VERSION ""

NS_ :

BS_:

BU_:

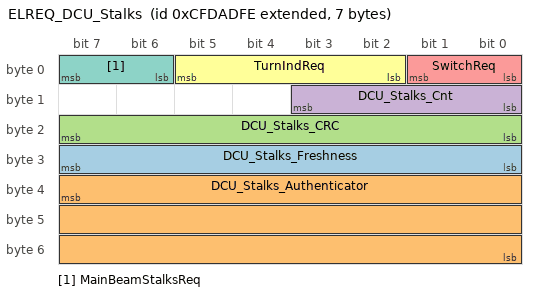
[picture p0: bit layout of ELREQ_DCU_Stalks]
BO_ 2365435390 ELREQ_DCU_Stalks: 7 Vector__XXX
 SG_ DCU_Stalks_Freshness : 31|8@0+ (1,0) [0|255] "" Vector__XXX
 SG_ DCU_Stalks_Authenticator : 39|24@0+ (1,0) [0|16777215] "" Vector__XXX
 SG_ DCU_Stalks_CRC : 16|8@1+ (1,0) [0|0] "" Vector__XXX
 SG_ DCU_Stalks_Cnt : 8|4@1+ (1,0) [0|0] "" Vector__XXX
 SG_ SwitchReq : 0|2@1+ (1,0) [0|3] "" Vector__XXX
 SG_ TurnIndReq : 2|4@1+ (1,0) [0|3] "" Vector__XXX
 SG_ MainBeamStalksReq : 6|2@1+ (1,0) [0|3] "" Vector__XXX

BO_ 2381722110 ELSTS: 1 Vector__XXX
 SG_ LampState : 0|3@1+ (1,0) [0|7] "" Vector__XXX
 SG_ ELSReadyToSleep : 3|2@1+ (1,0) [0|3] "" Vector__XXX

CM_ "$File: //depot/auto/dbc/Software_Modules/Exterior_Lights/ExtLightsSystem/0.3.4.0/ExtLightsSystem.dbc $
$Change: 215975 $
$DateTime: 2024/08/21 10:05:30 $
$Revision: #1 $";
CM_ BO_ 2365435390 "The message containing the request on external light sources from the operator's external light control switch(s).";
CM_ SG_ 2365435390 SwitchReq "A 2 bit parameter to indicate the selected position of operator's switch";
CM_ SG_ 2365435390 TurnIndReq "A 4 bit parameter to indicate the selected position of the operator's turn signal stalk";
CM_ SG_ 2365435390 MainBeamStalksReq "A 2 bit parameter to indicate the selected position of the operator's main light stalk";
CM_ BO_ 2381722110 "This lighting message is a response to the request for lighting data in the Exterior Lighting Command message.";
CM_ SG_ 2381722110 LampState "This parameter provides measured data from a center brake lamps

00 De activated
01 Activated
10 Fault Detected
11 Not Available";
BA_DEF_  "DBName" STRING ;
BA_DEF_ SG_  "SigType" ENUM  "Default","Range","RangeSigned","ASCII","Discrete","Control","ReferencePGN","DTC","StringDelimiter","StringLength","StringLengthControl","MessageCounter","MessageChecksum";
BA_DEF_ SG_  "GenSigSendType" ENUM  "Cyclic","OnWrite","OnWriteWithRepetition","OnChange","OnChangeWithRepetition","IfActive","IfActiveWithRepetition","NoSigSendType";
BA_DEF_ SG_  "GenSigILSupport" ENUM  "No","Yes";
BA_DEF_ SG_  "GenSigEVName" STRING ;
BA_DEF_ BO_  "GenMsgCycleTimeFast" INT 0 3600000;
BA_DEF_ BO_  "GenMsgILSupport" ENUM  "No","Yes";
BA_DEF_ BO_  "GenMsgDelayTime" INT 0 1000;
BA_DEF_ BO_  "GenMsgRequestable" INT 0 1;
BA_DEF_ BO_  "GenMsgSendType" ENUM  "cyclic","NotUsed","NotUsed","NotUsed","NotUsed","NotUsed","NotUsed","IfActive","noMsgSendType";
BA_DEF_ BO_  "VFrameFormat" ENUM  "StandardCAN","ExtendedCAN","reserved","J1939PG";
BA_DEF_ BO_  "GenMsgCycleTime" INT 0 3600000;
BA_DEF_ BO_  "SendOnChange" ENUM  "No","Yes";
BA_DEF_ BU_  "NmStationAddress" INT 0 255;
BA_DEF_  "SAE_J1939_DA_SpecVersion" STRING ;
BA_DEF_  "SAE_J1939_81_SpecVersion" STRING ;
BA_DEF_  "DatabaseVersion" STRING ;
BA_DEF_  "BusType" STRING ;
BA_DEF_  "ProtocolType" STRING ;
BA_DEF_  "SAE_J1939_75_SpecVersion" STRING ;
BA_DEF_  "SAE_J1939_21_SpecVersion" STRING ;
BA_DEF_  "SAE_J1939_73_SpecVersion" STRING ;
BA_DEF_  "SAE_J1939_71_SpecVersion" STRING ;
BA_DEF_ BO_  "Producer" STRING ;
BA_DEF_DEF_  "DBName" "";
BA_DEF_DEF_  "SigType" "Default";
BA_DEF_DEF_  "GenSigSendType" "NoSigSendType";
BA_DEF_DEF_  "GenSigILSupport" "Yes";
BA_DEF_DEF_  "GenSigEVName" "Env@Nodename_@Signame";
BA_DEF_DEF_  "GenMsgCycleTimeFast" 0;
BA_DEF_DEF_  "GenMsgILSupport" "Yes";
BA_DEF_DEF_  "GenMsgDelayTime" 0;
BA_DEF_DEF_  "GenMsgRequestable" 1;
BA_DEF_DEF_  "GenMsgSendType" "noMsgSendType";
BA_DEF_DEF_  "VFrameFormat" "J1939PG";
BA_DEF_DEF_  "GenMsgCycleTime" 0;
BA_DEF_DEF_  "SendOnChange" "No";
BA_DEF_DEF_  "NmStationAddress" 254;
BA_DEF_DEF_  "SAE_J1939_DA_SpecVersion" "";
BA_DEF_DEF_  "SAE_J1939_81_SpecVersion" "";
BA_DEF_DEF_  "DatabaseVersion" "";
BA_DEF_DEF_  "BusType" "";
BA_DEF_DEF_  "ProtocolType" "";
BA_DEF_DEF_  "SAE_J1939_75_SpecVersion" "";
BA_DEF_DEF_  "SAE_J1939_21_SpecVersion" "";
BA_DEF_DEF_  "SAE_J1939_73_SpecVersion" "";
BA_DEF_DEF_  "SAE_J1939_71_SpecVersion" "";
BA_DEF_DEF_  "Producer" "";
BA_ "SAE_J1939_DA_SpecVersion" "2015-01";
BA_ "SAE_J1939_81_SpecVersion" "2012-05";
BA_ "DatabaseVersion" "8.5";
BA_ "BusType" "CAN";
BA_ "ProtocolType" "J1939";
BA_ "SAE_J1939_75_SpecVersion" "2012-05";
BA_ "SAE_J1939_21_SpecVersion" "2006-10";
BA_ "SAE_J1939_73_SpecVersion" "2012-10";
BA_ "SAE_J1939_71_SpecVersion" "2012-10";
BA_ "DBName" "demo";
BA_ "Producer" BO_ 2365435390 "UICS";
BA_ "GenMsgDelayTime" BO_ 2365435390 10;
BA_ "GenMsgSendType" BO_ 2365435390 0;
BA_ "GenMsgCycleTime" BO_ 2365435390 1000;
BA_ "SendOnChange" BO_ 2365435390 1;
BA_ "Producer" BO_ 2381722110 "ELS";
BA_ "GenMsgSendType" BO_ 2381722110 0;
BA_ "GenMsgCycleTime" BO_ 2381722110 1000;
BA_ "SendOnChange" BO_ 2381722110 1;
BA_ "GenMsgDelayTime" BO_ 2381722110 10;
BA_ "SigType" SG_ 2365435390 DCU_Stalks_CRC 12;
BA_ "SigType" SG_ 2365435390 DCU_Stalks_Cnt 11;
VAL_ 2365435390 SwitchReq 3 "Not available" 2 "Reserved" 1 "Pressed" 0 "No Action" ;
VAL_ 2365435390 TurnIndReq 5 "Not available" 4 "Full Down" 3 "Half Down" 2 "Full Up" 1 "Half Up" 0 "No Action" ;
VAL_ 2365435390 MainBeamStalksReq 3 "Not available" 2 "Full Pull" 1 "Half Pull" 0 "No Action" ;
VAL_ 2381722110 LampState 7 "Not Available" 3 "No Command" 2 "Fault Detected" 1 "Activated" 0 "De activated" ;
VAL_ 2381722110 ELSReadyToSleep 3 "Not Available" 2 "Fault" 1 "Ready" 0 "Not Ready" ;
